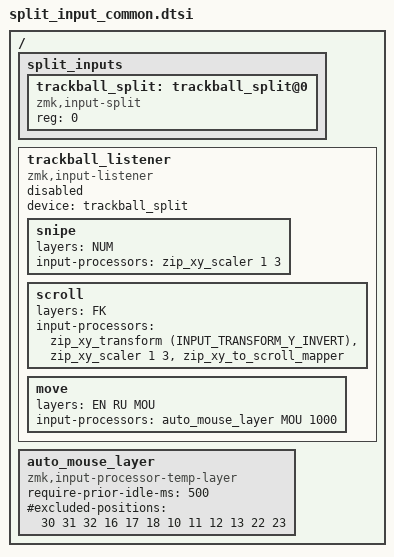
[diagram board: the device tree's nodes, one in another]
#include <dt-bindings/zmk/input_transform.h>
#include <input/processors.dtsi>

#define EN 0
#define RU 1
#define MOU 2
#define FK 3
#define SYE 4
#define SYR 5 
#define NUM 6 

/ {
  split_inputs {
    #address-cells = <1>;
    #size-cells = <0>;

    trackball_split: trackball_split@0 {
      compatible = "zmk,input-split";
      reg = <0>;
    };
  };

  trackball_listener: trackball_listener {
    compatible = "zmk,input-listener";
    status = "disabled";
    device = <&trackball_split>;

    snipe {
      layers = <NUM>;
      input-processors = <&zip_xy_scaler 1 3>;
    };

    scroll {
      layers = <FK>;
      input-processors = <&zip_xy_transform (INPUT_TRANSFORM_Y_INVERT)>, <&zip_xy_scaler 1 3>, <&zip_xy_to_scroll_mapper>;
    };

    move {
      layers = <EN RU MOU>;
      input-processors = <&auto_mouse_layer MOU 1000>;
    };
 };

  auto_mouse_layer: auto_mouse_layer {
    compatible = "zmk,input-processor-temp-layer";
    #input-processor-cells = <2>;
    require-prior-idle-ms = <500>;
    #excluded-positions = <30 31 32 16 17 18 10 11 12 13 22 23>;
  };
};
